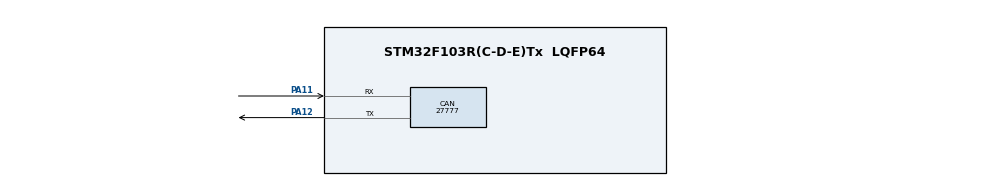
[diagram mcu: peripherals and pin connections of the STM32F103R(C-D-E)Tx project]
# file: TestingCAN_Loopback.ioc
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CAN.BS1=CAN_BS1_13TQ
CAN.BS2=CAN_BS2_4TQ
CAN.CalculateBaudRate=27777
CAN.CalculateTimeBit=36000.00
CAN.CalculateTimeQuantum=2000.0
CAN.Mode=CAN_MODE_LOOPBACK
Mcu.Family=STM32F1
Mcu.Name=STM32F103R(C-D-E)Tx
Mcu.Package=LQFP64
NVIC.PriorityGroup=NVIC_PRIORITYGROUP_4
NVIC.USB_LP_CAN1_RX0_IRQn=true\:0\:0\:false\:false\:true\:true\:true
PA11.GPIO_PuPd=GPIO_NOPULL
PA11.Mode=CAN_Activate
PA11.Signal=CAN_RX
PA12.Mode=CAN_Activate
PA12.Signal=CAN_TX
PA13.Mode=Serial_Wire
PA13.Signal=SYS_JTMS-SWDIO
PA14.Mode=Serial_Wire
PA14.Signal=SYS_JTCK-SWCLK
ProjectManager.HeapSize=0x200
ProjectManager.StackSize=0x400
ProjectManager.TargetToolchain=STM32CubeIDE
RCC.APB1Freq_Value=8000000
RCC.APB2Freq_Value=8000000
board=custom

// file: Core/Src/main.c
/* USER CODE BEGIN Header */
/**
  ******************************************************************************
  * @file           : main.c
  * @brief          : Main program body
  ******************************************************************************
  * @attention
  *
  * <h2><center>&copy; Copyright (c) 2023 STMicroelectronics.
  * All rights reserved.</center></h2>
  *
  * This software component is licensed by ST under BSD 3-Clause license,
  * the "License"; You may not use this file except in compliance with the
  * License. You may obtain a copy of the License at:
  *                        opensource.org/licenses/BSD-3-Clause
  *
  ******************************************************************************
  */
/* USER CODE END Header */
#include "main.h"

CAN_HandleTypeDef hcan;

void SystemClock_Config(void);
static void MX_GPIO_Init(void);
static void MX_CAN_Init(void);

/* USER CODE BEGIN 0 */
CAN_TxHeaderTypeDef TxHeader;
CAN_RxHeaderTypeDef RxHeader;
uint8_t TxData[8];
uint8_t RxData[8];
uint32_t TxMailbox[3]; //added [4]

uint8_t count = 99;
   //HAL_CAN_RxFIFO0MsgPendingCallback
//void HAL_CAN_RxFifo0MsgPendingCallback(CAN_HandleTypeDef *hcan)
  void HAL_CAN_RxFifo0MsgPendingCallback(CAN_HandleTypeDef *hcan)
{
	HAL_CAN_GetRxMessage(hcan, CAN_RX_FIFO0, &RxHeader, RxData);
  count++; //added this line
}
//void HAL_TIM_PeriodElapsedCallback(TIM_HandleTypeDef *htim){
//	count++;
//}

//TxHeader.IDE = 0;
/* USER CODE END 0 */

int main(void)
{

  /* MCU Configuration--------------------------------------------------------*/

  /* Reset of all peripherals, Initializes the Flash interface and the Systick. */
  HAL_Init();

  /* Configure the system clock */
  SystemClock_Config();

  /* Initialize all configured peripherals */
  MX_GPIO_Init();
  MX_CAN_Init();
  /* USER CODE BEGIN 2 */
  HAL_CAN_Start(&hcan);
  HAL_CAN_ActivateNotification(&hcan, CAN_IT_RX_FIFO0_MSG_PENDING);
  //__enable_irq();
  //HAL_TIM_Base_Start_IT(&htim2);
  TxHeader.DLC = 1;
  TxHeader.ExtId = 0;
  TxHeader.IDE = CAN_ID_STD;
  TxHeader.RTR = CAN_RTR_DATA; //added this line
  TxHeader.StdId = 0x111; //changed from 0x103 to 0x111
  TxHeader.TransmitGlobalTime = DISABLE;

  TxData[0] = 0x01; //added 4 bytes of data instead of one
  TxData[1] = 0x02;
  TxData[2] = 0x03;
  //TxData[3] = 0x04;

if (HAL_CAN_AddTxMessage(&hcan, &TxHeader, &TxData[0], &TxMailbox[0]) != HAL_OK)
  {
	count = 0;
	Error_Handler();
  }
  if (HAL_CAN_AddTxMessage(&hcan, &TxHeader, &TxData[1], &TxMailbox[1]) != HAL_OK)
  {
	  count = 1;
	  Error_Handler();
  }
  if (HAL_CAN_AddTxMessage(&hcan, &TxHeader, &TxData[2], &TxMailbox[2]) != HAL_OK)
  {
	  count = 2;
	  Error_Handler();
  }

  //if (HAL_CAN_AddTxMessage(&hcan, &TxHeader, &TxData[3], &TxMailbox[3]) != HAL_OK)
  //{
	//  count = 3;
	 // Error_Handler();
  //}

  //HAL_CAN_AddTxMessage(&hcan, &TxHeader, TxData, &TxMailbox); //used above code instead //why do we need & for TxMailbox??
  //__enable_irq();
  /* USER CODE END 2 */

  /* Infinite loop */
  /* USER CODE BEGIN WHILE */
  while (1)
  {
	  TxData[0] = 0x09;
	  HAL_CAN_AddTxMessage(&hcan, &TxHeader, TxData, TxMailbox);
	  HAL_Delay(500);
	  //for(int i=0;i<99;i++);
	  //int done =1;
    /* USER CODE END WHILE */

  }
}

void SystemClock_Config(void)
{
  RCC_OscInitTypeDef RCC_OscInitStruct = {0};
  RCC_ClkInitTypeDef RCC_ClkInitStruct = {0};

  /** Initializes the RCC Oscillators according to the specified parameters
  * in the RCC_OscInitTypeDef structure.
  */
  RCC_OscInitStruct.OscillatorType = RCC_OSCILLATORTYPE_HSI;
  RCC_OscInitStruct.HSIState = RCC_HSI_ON;
  RCC_OscInitStruct.HSICalibrationValue = RCC_HSICALIBRATION_DEFAULT;
  RCC_OscInitStruct.PLL.PLLState = RCC_PLL_NONE;
  if (HAL_RCC_OscConfig(&RCC_OscInitStruct) != HAL_OK)
  {
    Error_Handler();
  }
  /** Initializes the CPU, AHB and APB buses clocks
  */
  RCC_ClkInitStruct.ClockType = RCC_CLOCKTYPE_HCLK|RCC_CLOCKTYPE_SYSCLK
                              |RCC_CLOCKTYPE_PCLK1|RCC_CLOCKTYPE_PCLK2;
  RCC_ClkInitStruct.SYSCLKSource = RCC_SYSCLKSOURCE_HSI;
  RCC_ClkInitStruct.AHBCLKDivider = RCC_SYSCLK_DIV1;
  RCC_ClkInitStruct.APB1CLKDivider = RCC_HCLK_DIV1;
  RCC_ClkInitStruct.APB2CLKDivider = RCC_HCLK_DIV1;

  if (HAL_RCC_ClockConfig(&RCC_ClkInitStruct, FLASH_LATENCY_0) != HAL_OK)
  {
    Error_Handler();
  }
}

static void MX_CAN_Init(void)
{

  hcan.Instance = CAN1;
  hcan.Init.Prescaler = 16;
  hcan.Init.Mode = CAN_MODE_LOOPBACK;
  hcan.Init.SyncJumpWidth = CAN_SJW_1TQ;
  hcan.Init.TimeSeg1 = CAN_BS1_13TQ;
  hcan.Init.TimeSeg2 = CAN_BS2_4TQ;
  hcan.Init.TimeTriggeredMode = DISABLE;
  hcan.Init.AutoBusOff = DISABLE;
  hcan.Init.AutoWakeUp = DISABLE;
  hcan.Init.AutoRetransmission = DISABLE;
  hcan.Init.ReceiveFifoLocked = DISABLE;
  hcan.Init.TransmitFifoPriority = DISABLE;
  if (HAL_CAN_Init(&hcan) != HAL_OK)
  {
    Error_Handler();
  }
  /* USER CODE BEGIN CAN_Init 2 */
  CAN_FilterTypeDef canfilterconfig;

  canfilterconfig.FilterActivation = CAN_FILTER_ENABLE; //ENABLE
  canfilterconfig.FilterBank = 10; //0x0000
  canfilterconfig.FilterFIFOAssignment = CAN_RX_FIFO0;
  canfilterconfig.FilterIdHigh = 0x111<<5; //changed from 0x0000
  canfilterconfig.FilterIdLow = 0x0000;
  canfilterconfig.FilterMaskIdHigh = 0x1<<13; //changed from 0
  canfilterconfig.FilterMaskIdLow = 0x0000;
  canfilterconfig.FilterMode = CAN_FILTERMODE_IDMASK;
  canfilterconfig.FilterScale = CAN_FILTERSCALE_32BIT;
  canfilterconfig.SlaveStartFilterBank = 13; // changed from 0

  HAL_CAN_ConfigFilter(&hcan, &canfilterconfig);

  //HAL_NVIC_SetPriority(IRQn, PreemptPriority, SubPriority)

  /* USER CODE END CAN_Init 2 */

}

static void MX_GPIO_Init(void)
{

  /* GPIO Ports Clock Enable */
  __HAL_RCC_GPIOA_CLK_ENABLE();

}

/* USER CODE BEGIN 4 */
//void HAL_CAN_RxFIFO0MsgPendingCallback(CAN_HandleTypeDef *hcan)
//{
//	HAL_CAN_GetRxMessage(hcan, CAN_RX_FIFO0, &RxHeader, RxData);
//}
/* USER CODE END 4 */

void Error_Handler(void)
{
  __disable_irq();
  while (1)
  {
  }
}

/************************ (C) COPYRIGHT STMicroelectronics *****END OF FILE****/
